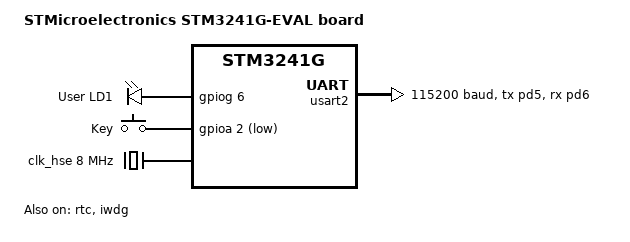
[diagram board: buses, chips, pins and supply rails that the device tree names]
/*
 * Copyright (c) 2017 Linaro Limited
 *
 * SPDX-License-Identifier: Apache-2.0
 */

/dts-v1/;
#include <st/f4/stm32f417Xg.dtsi>
#include <st/f4/stm32f417i(e-g)hx-pinctrl.dtsi>
#include <zephyr/dt-bindings/input/input-event-codes.h>

/ {
	model = "STMicroelectronics STM3241G-EVAL board";
	compatible = "st,stm3241g-eval";

	chosen {
		zephyr,console = &usart2;
		zephyr,shell-uart = &usart2;
		zephyr,sram = &sram0;
		zephyr,flash = &flash0;
	};

	leds {
		compatible = "gpio-leds";
		green_led_1: led_1 {
			gpios = <&gpiog 6 GPIO_ACTIVE_HIGH>;
			label = "User LD1";
		};
	};

	gpio_keys {
		compatible = "gpio-keys";
		user_button: button {
			label = "Key";
			gpios = <&gpioa 2 GPIO_ACTIVE_LOW>;
			zephyr,code = <INPUT_KEY_0>;
		};
	};

	aliases {
		led0 = &green_led_1;
		sw0 = &user_button;
		watchdog0 = &iwdg;
	};
};

&clk_lsi {
	status = "okay";
};

&clk_hse {
	clock-frequency = <DT_FREQ_M(8)>;
	status = "okay";
};

&pll {
	div-m = <8>;
	mul-n = <336>;
	div-p = <2>;
	div-q = <7>;
	clocks = <&clk_hse>;
	status = "okay";
};

&rcc {
	clocks = <&pll>;
	clock-frequency = <DT_FREQ_M(168)>;
	ahb-prescaler = <1>;
	apb1-prescaler = <4>;
	apb2-prescaler = <2>;
};

&usart2 {
	pinctrl-0 = <&usart2_tx_pd5 &usart2_rx_pd6>;
	pinctrl-names = "default";
	current-speed = <115200>;
	status = "okay";
};

&rtc {
	clocks = <&rcc STM32_CLOCK_BUS_APB1 0x10000000>,
		 <&rcc STM32_SRC_LSI RTC_SEL(2)>;
	status = "okay";
};

&iwdg {
	status = "okay";
};
